# Q32M210 register map
File version: 1.0
Registers are 32-bit, read-write, no defined reset value unless marked. A register's access mark holds for its fields unless they carry their own. Offsets are from the block's base; [hi:lo] are bit positions; {n}, {i} and the like mark numbered series.

## Analog_Front-End
Base 0x40000008
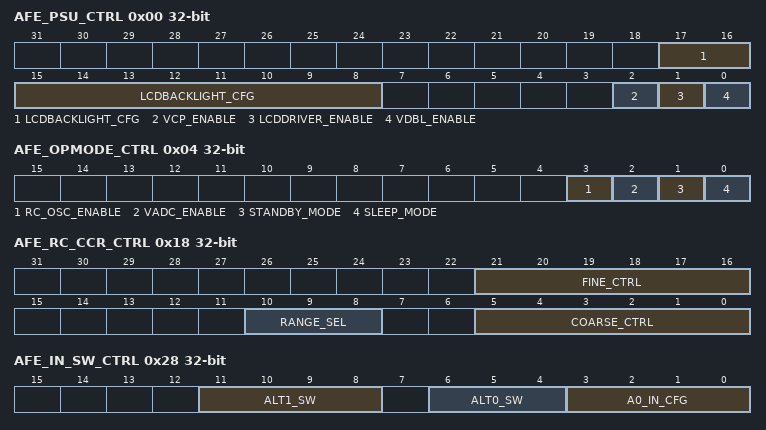
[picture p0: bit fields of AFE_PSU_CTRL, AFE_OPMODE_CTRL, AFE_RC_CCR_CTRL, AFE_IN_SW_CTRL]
0x00 AFE_PSU_CTRL — Power Supply Charge Pump and LCD Backlight Control
  [17:8] LCDBACKLIGHT_CFG — Select whether the LCD driver backlight is currently enabled and select the current provided to the backlight
    0=LCDBACKLIGHT_DISABLE (Disable the LCD driver backlight); 1=LCDBACKLIGHT_1_INOM (LCD driver backlight current supplied is the nominal setting); 3=LCDBACKLIGHT_2_INOM (LCD driver backlight current supplied is 2 times the nominal setting); 7=LCDBACKLIGHT_3_INOM (LCD driver backlight current supplied is 3 times the nominal setting); 15=LCDBACKLIGHT_4_INOM (LCD driver backlight current supplied is 4 times the nominal setting); 31=LCDBACKLIGHT_5_INOM (LCD driver backlight current supplied is 5 times the nominal setting); 63=LCDBACKLIGHT_6_INOM (LCD driver backlight current supplied is 6 times the nominal setting); 127=LCDBACKLIGHT_7_INOM (LCD driver backlight current supplied is 7 times the nominal setting); 255=LCDBACKLIGHT_8_INOM (LCD driver backlight current supplied is 8 times the nominal setting); 0x1FF=LCDBACKLIGHT_9_INOM (LCD driver backlight current supplied is 9 times the nominal setting); 0x3FF=LCDBACKLIGHT_10_INOM (LCD driver backlight current supplied is 10 times the nominal setting)
  [2] VCP_ENABLE — Select whether the charge pump LDO is currently enabled
    0=VCP_DISABLE (Disable the charge pump LDO); 1=VCP_ENABLE (Enable the charge pump LDO)
  [1] LCDDRIVER_ENABLE — Select whether the LCD driver is currently enabled
    0=LCDDRIVER_DISABLE (Disable the LCD driver); 1=LCDDRIVER_ENABLE (Enable the LCD driver)
  [0] VDBL_ENABLE — Select whether the VDBL is enabled
    0=VDBL_DISABLE (Disable VDBL); 1=VDBL_ENABLE (Enable VDBL)
0x04 AFE_OPMODE_CTRL — Operation Control
  [3] RC_OSC_ENABLE — Select whether the RC oscillator is enabled
    0=RC_OSC_DISABLE (The RC oscillator is disabled); 1=RC_OSC_ENABLE (The RC oscillator is enabled)
  [2] VADC_ENABLE — Select whether VADC is enabled
    0=VADC_DISABLE (VADC supply is disabled); 1=VADC_ENABLE (VADC supply is enabled)
  [1] STANDBY_MODE — Control standby mode selection
    0=STANDBY_MODE_DISABLE (Device operates in normal mode); 1=STANDBY_MODE_ENABLE (Device transitions to standby mode)
  [0] SLEEP_MODE — Control sleep mode selection
    0=SLEEP_MODE_DISABLE (Device operates in normal mode); 1=SLEEP_MODE_ENABLE (Device transitions to sleep mode)
0x08 AFE_32K_CCR_CTRL — 32 kHz Crystal Clock Calibration Control
  [7:0] CCR_CTRL — Trimming of the 32 kHz crystal oscillator in -0.012 Hz or +0.096 Hz steps
0x10 AFE_48M_CCR_CTRL — 48 MHz Crystal Clock Calibration Control
  [7:0] CCR_CTRL — Trimming of the 48 MHz crystal oscillator
0x18 AFE_RC_CCR_CTRL — RC Clock Calibration Control
  [21:16] FINE_CTRL — Fine trimming of RC oscillator frequency
  [10:8] RANGE_SEL — Select the frequency range for the RC oscillator
    0=RC_OSC_FREQ_RANGE_7 (Select RC oscillator frequency range 7); 1=RC_OSC_FREQ_RANGE_6 (Select RC oscillator frequency range 6); 2=RC_OSC_FREQ_RANGE_5 (Select RC oscillator frequency range 5); 3=RC_OSC_FREQ_RANGE_4 (Select RC oscillator frequency range 4); 4=RC_OSC_FREQ_RANGE_3 (Select RC oscillator frequency range 3); 5=RC_OSC_FREQ_RANGE_2 (Select RC oscillator frequency range 2); 6=RC_OSC_FREQ_RANGE_1 (Select RC oscillator frequency range 1); 7=RC_OSC_FREQ_RANGE_0 (Select RC oscillator frequency range 0)
  [5:0] COARSE_CTRL — Coarse trimming of RC oscillator frequency
0x28 AFE_IN_SW_CTRL — Input Control and Configuration
  [11:8] ALT1_SW — Configure the connection to the ALT1 pad and multiplexer M0
    0=ALT1_SW_SEL_NONE (All pads IN3 to IN7 connected to multiplexer M0); 1=ALT1_SW_SEL_IN3 (IN3 connected to ALT1 pad, IN4 to IN7 connected to multiplexer M0); 2=ALT1_SW_SEL_IN4 (IN4 connected to ALT1 pad, IN3, IN5 to IN7 connected to multiplexer M0); 3=ALT1_SW_SEL_IN5 (IN5 connected to ALT1 pad, IN3 to IN4, IN6 to IN7 connected to multiplexer M0); 4=ALT1_SW_SEL_IN6 (IN6 connected to ALT1 pad, IN3 to IN5, IN7 connected to multiplexer M0); 5=ALT1_SW_SEL_IN7 (IN7 connected to ALT1 pad, IN3 to IN6 connected to multiplexer M0); {v}=ALT1_SW_SEL_M0_IN{v-3} (IN{v-3} connected to ALT1 pad, IN3 to IN7 connected to multiplexer M0) (v=6..10); 15=ALT1_SW_DISABLE (Switches disabled)
  [6:4] ALT0_SW — Configure the connection to the ALT0 pad and multiplexer M0
    0=ALT0_SW_SEL_NONE (All pads IN0 to IN2 connected to multiplexer M0); 1=ALT0_SW_SEL_IN0 (IN0 connected to ALT0 pad, IN1 and IN2 connected to multiplexer M0); 2=ALT0_SW_SEL_IN1 (IN1 connected to ALT0 pad, IN0 and IN2 connected to multiplexer M0); 3=ALT0_SW_SEL_IN2 (IN2 connected to ALT0 pad, IN0 and IN1 connected to multiplexer M0); 4=ALT0_SW_SEL_M0_IN0 (IN0 connected to ALT0 pad, IN0 to IN2 connected to multiplexer M0); 5=ALT0_SW_SEL_M0_IN1 (IN1 connected to ALT0 pad, IN0 to IN2 connected to multiplexer M0); 6=ALT0_SW_SEL_M0_IN2 (IN2 connected to ALT0 pad, IN0 to IN2 connected to multiplexer M0); 7=ALT0_SW_DISABLE (Switches disabled)
  [3:0] A0_IN_CFG — Configuration of input to the AO negative terminal input
    {v}=A0_CFG_SEL_IN{v} (Connect negative terminal of A0 to IN{v}) (v=0..7); 8=A0_CFG_SEL_DISABLE (Mux M0 powered off)
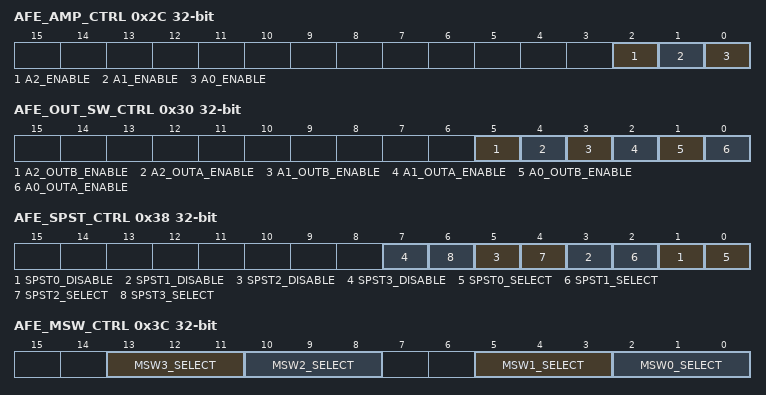
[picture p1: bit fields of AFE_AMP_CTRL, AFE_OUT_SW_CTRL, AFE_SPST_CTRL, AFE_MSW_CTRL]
0x2C AFE_AMP_CTRL — Opamp Control
  [2] A2_ENABLE — Enable opamp A2
    0=A2_DISABLE (Disable opamp A2); 1=A2_ENABLE (Enable opamp A2)
  [1] A1_ENABLE — Enable opamp A1
    0=A1_DISABLE (Disable opamp A1); 1=A1_ENABLE (Enable opamp A1)
  [0] A0_ENABLE — Enable opamp A0
    0=A0_DISABLE (Disable opamp A0); 1=A0_ENABLE (Enable opamp A0)
0x30 AFE_OUT_SW_CTRL — Output Control and Configuration
  [5] A2_OUTB_ENABLE — Opamp A2 B output connection
    0=A2_OUTB_DISABLE (Disable A2 output B); 1=A2_OUTB_ENABLE (Enable A2 output B)
  [4] A2_OUTA_ENABLE — Opamp A2 A output connection
    0=A2_OUTA_DISABLE (Disable A2 output A); 1=A2_OUTA_ENABLE (Enable A2 output A)
  [3] A1_OUTB_ENABLE — Opamp A1 B output connection
    0=A1_OUTB_DISABLE (Disable A1 output B); 1=A1_OUTB_ENABLE (Enable A1 output B)
  [2] A1_OUTA_ENABLE — Opamp A1 A output connection
    0=A1_OUTA_DISABLE (Disable A1 output A); 1=A1_OUTA_ENABLE (Enable A1 output A)
  [1] A0_OUTB_ENABLE — Opamp A0 B output connection
    0=A0_OUTB_DISABLE (Disable A0 output B); 1=A0_OUTB_ENABLE (Enable A0 output B)
  [0] A0_OUTA_ENABLE — Opamp A0 A output connection
    0=A0_OUTA_DISABLE (Disable A0 output A); 1=A0_OUTA_ENABLE (Enable A0 output A)
0x38 AFE_SPST_CTRL — SPST Switch Control
  [2n+1] SPST{n}_DISABLE (n=0..3) — Disable SPST switch {n}
    0=SPST{n}_ENABLE (Switch enabled); 1=SPST{n}_DISABLE (Switch diabled (no connection))
  [2n] SPST{n}_SELECT (n=0..3) — Select whether SPST switch {n} is open or closed
    0=SPST{n}_SEL_OPEN (Switch open); 1=SPST{n}_SEL_CLOSE (Switch closed)
0x3C AFE_MSW_CTRL — Multi-Switch Control
  [13:11] MSW3_SELECT — Select configuration for multi-switch 3
    0=MSW3_SEL_A (Connect MSW3 A to common); 1=MSW3_SEL_B (Connect MSW3 B to common); 2=MSW3_SEL_A_B (Connect MSW3 A and B to common); 3=MSW3_SEL_DISABLE (Common disconnected); 4=MSW3_SEL_PWM3 (MSW3 is configured by PWM3)
  [10:8] MSW2_SELECT — Select configuration for multi-switch 2
    0=MSW2_SEL_A (Connect MSW2 A to common); 1=MSW2_SEL_B (Connect MSW2 B to common); 2=MSW2_SEL_A_B (Connect MSW2 A and B to common); 3=MSW2_SEL_DISABLE (Common disconnected); 4=MSW2_SEL_PWM2 (MSW2 is configured by PWM2)
  [5:3] MSW1_SELECT — Select configuration for multi-switch 1
    0=MSW1_SEL_A (Connect MSW1 A to common); 1=MSW1_SEL_B (Connect MSW1 B to common); 2=MSW1_SEL_A_B (Connect MSW1 A and B to common); 3=MSW1_SEL_DISABLE (Common disconnected); 4=MSW1_SEL_PWM1 (MSW1 is configured by PWM1)
  [2:0] MSW0_SELECT — Select configuration for multi-switch 0
    0=MSW0_SEL_A (Connect MSW0 A to common); 1=MSW0_SEL_B (Connect MSW0 B to common); 2=MSW0_SEL_A_B (Connect MSW0 A and B to common); 3=MSW0_SEL_DISABLE (Common disconnected); 4=MSW0_SEL_PWM0 (MSW0 is configured by PWM0)
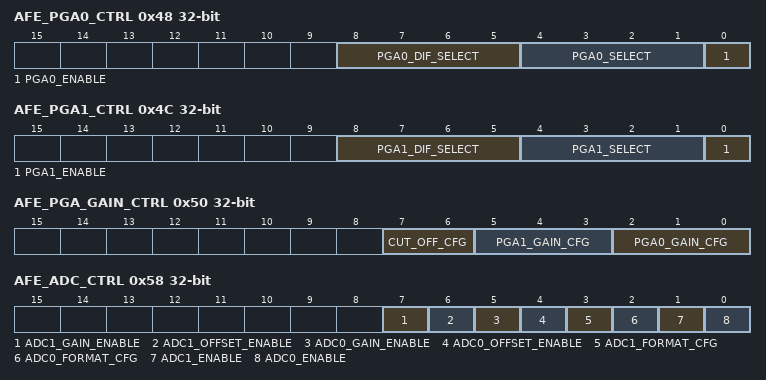
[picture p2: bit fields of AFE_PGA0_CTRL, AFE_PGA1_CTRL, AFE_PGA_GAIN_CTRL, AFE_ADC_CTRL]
0x48 AFE_PGA0_CTRL — Programmable Gain Amplifier 0 Control
  [8:5] PGA0_DIF_SELECT — Select subtractor for PGA0 input
    0=PGA0_DIF_SEL_VSS (PGA0 differential input is VSS); 1=PGA0_DIF_SEL_VBAT_2 (PGA0 differential input is VBAT/2); 2=PGA0_DIF_SEL_VBATA_2 (PGA0 differential input is VBATA/2); 3=PGA0_DIF_SEL_VREF (PGA0 differential input is VREF); 4=PGA0_DIF_SEL_OUT0 (PGA0 differential input is OUT0); 5=PGA0_DIF_SEL_OUT1 (PGA0 differential input is OUT1); 6=PGA0_DIF_SEL_OUT2 (PGA0 differential input is OUT2); 7=PGA0_DIF_SEL_A0REF (PGA0 differential input is A0REF); 8=PGA0_DIF_SEL_A1REF (PGA0 differential input is A1REF); 9=PGA0_DIF_SEL_A2REF (PGA0 differential input is A2REF); 10=PGA0_DIF_SEL_VWAKEUP (PGA0 differential input is VWAKEUP); 11=PGA0_DIF_SEL_VTS2 (PGA0 differential input is VTS2); 13=PGA0_DIF_SEL_AUX_IN1 (PGA0 differential input is AUX_IN1); 14=PGA0_DIF_SEL_AUX_IN0 (PGA0 differential input is AUX_IN0); 15=PGA0_DIF_SEL_VADC_2 (PGA0 differential input is VADC/2)
  [4:1] PGA0_SELECT — Select PGA0 primary input signal
    0=PGA0_SEL_VSS (PGA0 input is VSS); 1=PGA0_SEL_VBAT_2 (PGA0 input is VBAT/2); 2=PGA0_SEL_VBATA_2 (PGA0 input is VBATA/2); 3=PGA0_SEL_VREF (PGA0 input is VREF); 4=PGA0_SEL_OUT0 (PGA0 input is OUT0); 5=PGA0_SEL_OUT1 (PGA0 input is OUT1); 6=PGA0_SEL_OUT2 (PGA0 input is OUT2); 7=PGA0_SEL_A0REF (PGA0 input is A0REF); 8=PGA0_SEL_A1REF (PGA0 input is A1REF); 9=PGA0_SEL_A2REF (PGA0 input is A2REF); 10=PGA0_SEL_VWAKEUP (PGA0 input is VWAKEUP); 11=PGA0_SEL_VTS1 (PGA0 input is VTS1); 12=PGA0_SEL_AUX_IN2 (PGA0 input is AUX_IN2); 13=PGA0_SEL_AUX_IN1 (PGA0 input is AUX_IN1); 14=PGA0_SEL_AUX_IN0 (PGA0 input is AUX_IN0); 15=PGA0_SEL_VADC_2 (PGA0 input is VADC/2)
  [0] PGA0_ENABLE — Enable PGA0 amplifier
    0=PGA0_DISABLE (Disable PGA0); 1=PGA0_ENABLE (Enable PGA0)
0x4C AFE_PGA1_CTRL — Programmable Gain Amplifier 1 Control
  [8:5] PGA1_DIF_SELECT — Select subtractor for PGA1 input
    0=PGA1_DIF_SEL_VSS (PGA1 differential input is VSS); 1=PGA1_DIF_SEL_VBAT_2 (PGA1 differential input is VBAT/2); 2=PGA1_DIF_SEL_VBATA_2 (PGA1 differential input is VBATA/2); 3=PGA1_DIF_SEL_VREF (PGA1 differential input is VREF); 4=PGA1_DIF_SEL_OUT0 (PGA1 differential input is OUT0); 5=PGA1_DIF_SEL_OUT1 (PGA1 differential input is OUT1); 6=PGA1_DIF_SEL_OUT2 (PGA1 differential input is OUT2); 7=PGA1_DIF_SEL_A0REF (PGA1 differential input is A0REF); 8=PGA1_DIF_SEL_A1REF (PGA1 differential input is A1REF); 9=PGA1_DIF_SEL_A2REF (PGA1 differential input is A2REF); 10=PGA1_DIF_SEL_VWAKEUP (PGA1 differential input is VWAKEUP); 11=PGA1_DIF_SEL_VTS2 (PGA1 differential input is VTS2); 13=PGA1_DIF_SEL_AUX_IN1 (PGA1 differential input is AUX_IN1); 14=PGA1_DIF_SEL_AUX_IN0 (PGA1 differential input is AUX_IN0); 15=PGA1_DIF_SEL_VADC_2 (PGA1 differential input is VADC/2)
  [4:1] PGA1_SELECT — Select PGA1 primary input signal
    0=PGA1_SEL_VSS (PGA1 input is VSS); 1=PGA1_SEL_VBAT_2 (PGA1 input is VBAT/2); 2=PGA1_SEL_VBATA_2 (PGA1 input is VBATA/2); 3=PGA1_SEL_VREF (PGA1 input is VREF); 4=PGA1_SEL_OUT0 (PGA1 input is OUT0); 5=PGA1_SEL_OUT1 (PGA1 input is OUT1); 6=PGA1_SEL_OUT2 (PGA1 input is OUT2); 7=PGA1_SEL_A0REF (PGA1 input is A0REF); 8=PGA1_SEL_A1REF (PGA1 input is A1REF); 9=PGA1_SEL_A2REF (PGA1 input is A2REF); 10=PGA1_SEL_VWAKEUP (PGA1 input is VWAKEUP); 11=PGA1_SEL_VTS1 (PGA1 input is VTS1); 12=PGA1_SEL_AUX_IN2 (PGA1 input is AUX_IN2); 13=PGA1_SEL_AUX_IN1 (PGA1 input is AUX_IN1); 14=PGA1_SEL_AUX_IN0 (PGA1 input is AUX_IN0); 15=PGA1_SEL_VADC_2 (PGA1 input is VADC/2)
  [0] PGA1_ENABLE — Enable PGA1 amplifier
    0=PGA1_DISABLE (Disable PGA1); 1=PGA1_ENABLE (Enable PGA1)
0x50 AFE_PGA_GAIN_CTRL — Programmable Gain Amplifier Configuration and Control
  [7:6] CUT_OFF_CFG — Select cut-off frequency for anti-aliasing filter
    1=PGA_CUT_OFF_LOW (Low cut-off); 0=PGA_CUT_OFF_HIGH (High cut-off)
  [5:3] PGA1_GAIN_CFG — Select the gain for PGA1
    0=PGA1_GAIN_0DB (0 dB); 1=PGA1_GAIN_6DB (6 dB); 2=PGA1_GAIN_12DB (12 dB); 3=PGA1_GAIN_18DB (18 dB); 4=PGA1_GAIN_24DB (24 dB); 5=PGA1_GAIN_30DB (30 dB); 6=PGA1_GAIN_36DB (36 dB)
  [2:0] PGA0_GAIN_CFG — Select the gain for PGA0
    0=PGA0_GAIN_0DB (0 dB); 1=PGA0_GAIN_6DB (6 dB); 2=PGA0_GAIN_12DB (12 dB); 3=PGA0_GAIN_18DB (18 dB); 4=PGA0_GAIN_24DB (24 dB); 5=PGA0_GAIN_30DB (30 dB); 6=PGA0_GAIN_36DB (36 dB); 7=PGA0_GAIN_42DB (42 dB)
0x54 AFE_THRESHOLD_COMPARE_CTRL — Voltage Threshold Comparator Control
  [1:0] THRESHOLD — Enable and select the voltage threshold for the threshold comparator
    0=THRESHOLD_COMPARE_DISABLE (Disable the threshold comparatpr); 1=THRESHOLD_COMPARE_40MV (Threshold for the comparitor is 40 mV); 2=THRESHOLD_COMPARE_80MV (Threshold for the comparitor is 80 mV); 3=THRESHOLD_COMPARE_120MV (Threshold for the comparitor is 120 mV)
0x58 AFE_ADC_CTRL — ADC Configuration and Control
  [7] ADC1_GAIN_ENABLE — Enable the gain error correction multiplier for ADC1
    0=ADC1_GAIN_DISABLE (Disable the gain error correction multiplier for ADC1); 1=ADC1_GAIN_ENABLE (Enable the gain error correction multiplier for ADC1)
  [6] ADC1_OFFSET_ENABLE — Enable offset correction for ADC1
    0=ADC1_OFFSET_DISABLE (Disable offset correction for ADC1); 1=ADC1_OFFSET_ENABLE (Enable offset correction for ADC1)
  [5] ADC0_GAIN_ENABLE — Enable the gain error correction multiplier for ADC0
    0=ADC0_GAIN_DISABLE (Disable the gain error correction multiplier for ADC0); 1=ADC0_GAIN_ENABLE (Enable the gain error correction multiplier for ADC0)
  [4] ADC0_OFFSET_ENABLE — Enable offset correction for ADC0
    0=ADC0_OFFSET_DISABLE (Disable offset correction for ADC0); 1=ADC0_OFFSET_ENABLE (Enable offset correction for ADC0)
  [3] ADC1_FORMAT_CFG — ADC output number format
    0=ADC1_FORMAT_TWOS_COMP ("2's complement output mode"); 1=ADC1_FORMAT_UNSIGNED_INT (Unsigned integer output mode)
  [2] ADC0_FORMAT_CFG — ADC output number format
    0=ADC0_FORMAT_TWOS_COMP ("2's complement output mode"); 1=ADC0_FORMAT_UNSIGNED_INT (Unsigned integer output mode)
  [1] ADC1_ENABLE — Enable ADC1
    0=ADC1_DISABLE; 1=ADC1_ENABLE
  [0] ADC0_ENABLE — Enable ADC0
    0=ADC0_DISABLE; 1=ADC0_ENABLE
0x5C AFE_ADC0_DATA — ADC0 Output
  [31:16] ALIGN — Output from ADC0
0x60 AFE_ADC1_DATA — ADC1 Output
  [31:16] ALIGN — Output from ADC1
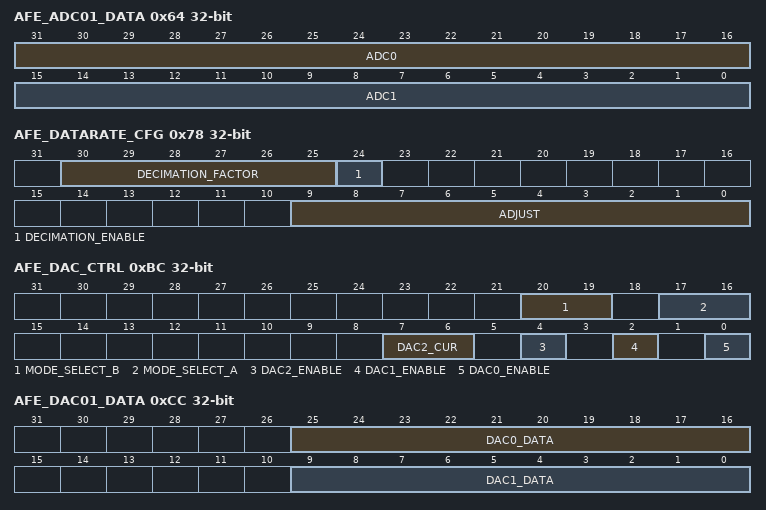
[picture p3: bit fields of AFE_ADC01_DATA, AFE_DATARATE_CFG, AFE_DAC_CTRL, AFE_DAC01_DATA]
0x64 AFE_ADC01_DATA — ADC 0 and 1 Shared Output
  [31:16] ADC0 — 16 MSBs of output from ADC0
  [15:0] ADC1 — 16 MSBs of output from ADC1
0x68 AFE_ADC0_OFFSET — ADC0 Offset Calibration
  [31:14] CAL — Offset value that is added to ADC0 output for calibration purposes
0x6C AFE_ADC1_OFFSET — ADC1 Offset Calibration
  [31:14] CAL — Offset value that is added to ADC1 output for calibration purposes
0x70 AFE_ADC0_GAIN — ADC0 Gain Calibration
  [31:14] CAL — Gain value that is multiplied to ADC0 output for calibration purposes
0x74 AFE_ADC1_GAIN — ADC1 Gain Calibration
  [31:14] CAL — Gain value that is multiplied to ADC1 output for calibration purposes
0x78 AFE_DATARATE_CFG — ADC Data Rate Configuration
  [30:25] DECIMATION_FACTOR — Set the decimation rate portion of the ADC data rate
  [24] DECIMATION_ENABLE — Enable the decimation filter
    1=DATARATE_DECIMATE_ENABLE (Decimation filter is enabled); 0=DATARATE_DECIMATE_DISABLE (Decimation filter is disabled)
  [9:0] ADJUST — Adjustment factor used to calculate the undecimated data rate
0x84 AFE_DATARATE_CFG1 — AFE Data Rate Mode Configuration
  [3:0] FREQ_MODE — Configure the oversampling mode used by the ADCs
{0x88+4i} AFE_PWM{i}_PERIOD (i=0..3) — PWM{i} Period Configuration
  [7:0] PWM{i}_PERIOD — Configure the number of cycles per period for PWM{i}
{0x98+4i} AFE_PWM{i}_HI (i=0..3) — PWM{i} Duty Cycle Configuration
  [7:0] PWM{i}_HI — Configure how many high cycles there are per period for PWM{i}
0xA8 AFE_TEMP_SENSE_CTRL — Temperature Sensor Control and Configuration
  [0] TEMP_SENSE_ENABLE — Enable temperature sensor circuitry
    0=TEMP_SENSE_DISABLE (Disable the temperature sensor); 1=TEMP_SENSE_ENABLE (Enable the temperature sensor)
0xB8 AFE_DAC0_REF_CTRL — DAC0 Voltage Reference control
  [1:0] DAC0_REF_CTRL — Select reference for DAC0
    0=DAC0_REF_SELECT_VREF (Select VREF as the DAC0 reference voltage); 1=DAC0_REF_SELECT_2VREF (Select 2*VREF as the DAC0 reference voltage); 2=DAC0_REF_SELECT_3VREF (Select 3*VREF as the DAC0 reference voltage)
0xBC AFE_DAC_CTRL — DAC Control and Configuration
  [20:19] MODE_SELECT_B — Select the operating mode for PGA1 input B
    0=PGA1_B_MODE_DISABLE (Disable PGA1 input B); 1=PGA1_B_MODE_1 (Set PGA1 input B for high-range inputs); 2=PGA1_B_MODE_0 (Set PGA1 input B for low-range inputs); 3=PGA1_B_MODE_2 (Set PGA1 input B for full-range inputs)
  [17:16] MODE_SELECT_A — Select the operating mode for PGA1 input A
    0=PGA1_A_MODE_DISABLE (Disable PGA1 input A); 1=PGA1_A_MODE_1 (Set PGA1 input A for high-range inputs); 2=PGA1_A_MODE_0 (Set PGA1 input A for low-range inputs); 3=PGA1_A_MODE_2 (Set PGA1 input A for full-range inputs)
  [7:6] DAC2_CUR — Select the DAC2 output drive current
    0=DAC2_CUR_NOMINAL (Nominal DAC2 output drive current); 1=DAC2_CUR_4_NOMINAL (DAC2 output drive current is 4 times nominal); 2=DAC2_CUR_10_NOMINAL (DAC2 output drive current is 10 times nominal); 3=DAC2_CUR_20_NOMINAL (DAC2 output drive current is 20 times nominal)
  [4] DAC2_ENABLE — Enable DAC2
    0=DAC2_DISABLE (Disable DAC2); 1=DAC2_ENABLE (Enable DAC2)
  [2] DAC1_ENABLE — Enable DAC1
    0=DAC1_DISABLE (Disable DAC1); 1=DAC1_ENABLE (Enable DAC1)
  [0] DAC0_ENABLE — Enable DAC0
    0=DAC0_DISABLE (Disable DAC0); 1=DAC0_ENABLE (Enable DAC0)
{0xC0+4i} AFE_DAC{i}_DATA (i=0..2) — DAC{i} Input Data
  [9:0] DAC{i}_DATA — Input data for DAC{i}
0xCC AFE_DAC01_DATA — DAC 0 and DAC 1 Input Data
  [25:16] DAC0_DATA — Input data for DAC0
  [9:0] DAC1_DATA — Input data for DAC1
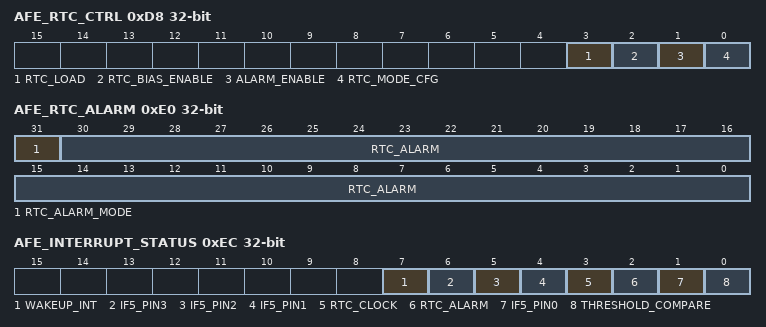
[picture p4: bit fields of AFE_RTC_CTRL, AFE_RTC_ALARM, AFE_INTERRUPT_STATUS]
0xD8 AFE_RTC_CTRL — RTC Clock Control
  [3] RTC_LOAD — Load the RTC counter and alarm configuration
    1=RTC_LOAD (Load the RTC counter and alarm configuration)
  [2] RTC_BIAS_ENABLE — Enable the real-time clock
    0=RTC_DISABLE (The real-time clock is disabled); 1=RTC_ENABLE (The real-time clock is enabled)
  [1] ALARM_ENABLE
    0=ALARM_DISABLE (Disable the RTC alarm); 1=ALARM_ENABLE (Enable the RTC alarm)
  [0] RTC_MODE_CFG — Set RTC operation mode
    0=RTC_RUN_MODE (Run the RTC clock, maintaining a calculation of the current time); 1=RTC_SET_MODE (Pause the RTC clock, allowing it to be set)
0xDC AFE_RTC_COUNT — RTC Count
  [31:0] RTC_COUNT — Current time based on the real-time clock
0xE0 AFE_RTC_ALARM — RTC Alarm Count
  [31] RTC_ALARM_MODE — Select between relative and absolute alarm mode
    0=ALARM_ABSOLUTE_MODE (The RTC alarm is triggered when RTC_ALARM matches the low 31 bits of RTC_COUNT); 1=ALARM_RELATIVE_MODE (The RTC alarm is triggered every RTC_ALARM RTC clock cycles)
  [30:0] RTC_ALARM — Real-time clock alarm setting
0xEC AFE_INTERRUPT_STATUS — Analog Interrupt Status
  [7] WAKEUP_INT — Analog general-purpose wakeup (IF5, pin 0) was the wakeup source
    0=WAKEUP_INT_CLEARED (No wakeup sources are active); 1=WAKEUP_INT_PEND (A wakeup source is active and will pend the wakeup interrupt if active)
  [6] IF5_PIN3 — General-purpose wakeup 3 (IF5, pin 3) was the wakeup source
    0=WAKEUP_IF5_PIN3_NOT_SET (Wakeup on GPIO IF5, pin 3 source not set); 1=WAKEUP_IF5_PIN3_SET (Wakeup on GPIO IF5, pin 3 source is set); 1=WAKEUP_IF5_PIN3_CLEAR (Clear the IF5, pin 3 wakeup GPIO source)
  [5] IF5_PIN2 — General-purpose wakeup 2 (IF5, pin 2) was the wakeup source
    0=WAKEUP_IF5_PIN2_NOT_SET (Wakeup on GPIO IF5, pin 2 source not set); 1=WAKEUP_IF5_PIN2_SET (Wakeup on GPIO IF5, pin 2 source is set); 1=WAKEUP_IF5_PIN2_CLEAR (Clear the IF5, pin 2 wakeup GPIO source)
  [4] IF5_PIN1 — General-purpose wakeup 1 (IF5, pin 1) was the wakeup source
    0=WAKEUP_IF5_PIN1_NOT_SET (Wakeup on GPIO IF5, pin 1 source not set); 1=WAKEUP_IF5_PIN1_SET (Wakeup on GPIO IF5, pin 1 source is set); 1=WAKEUP_IF5_PIN1_CLEAR (Clear the IF5, pin 1 wakeup GPIO source)
  [3] RTC_CLOCK — Indicate if an RTC clock interrupt has occurred
    0=RTC_CLOCK_NOT_SET (RTC clock interrupt has not occured); 1=RTC_CLOCK_SET (RTC clock interrupt has occured); 1=RTC_CLOCK_CLEAR (Clear the RTC clock interrupt)
  [2] RTC_ALARM — Indicate if an RTC alarm interrupt has occurred
    0=RTC_ALARM_NOT_SET (RTC alarm has not occured); 1=RTC_ALARM_SET (RTC alarm has occured); 1=RTC_ALARM_CLEAR (Clear the RTC alarm interrupt)
  [1] IF5_PIN0 — Indicate if an IF5, pin 0 specific wakeup interrupt has occurred
    0=WAKEUP_IF5_PIN0_NOT_SET (Wakeup on GPIO IF5, pin 0 source not set); 1=WAKEUP_IF5_PIN0_SET (Wakeup on GPIO IF5, pin 0 source is set); 1=WAKEUP_IF5_PIN0_CLEAR (Clear the IF5, pin 0 wakeup GPIO source)
  [0] THRESHOLD_COMPARE — Indicate if a threshold comparator event has occurred
    0=THRESHOLD_COMPARE_NOT_SET (Threshold comparator has not triggered); 1=THRESHOLD_COMPARE_SET (Voltage threshold comparator has triggered); 1=THRESHOLD_COMPARE_CLEAR (Clear the voltage threshold comparator status)
0xF0 AFE_RETENTION_DATA — General-Purpose Data Retention
  [7:0] RETENTION_DATA — Data storage register that retains state while in sleep mode
